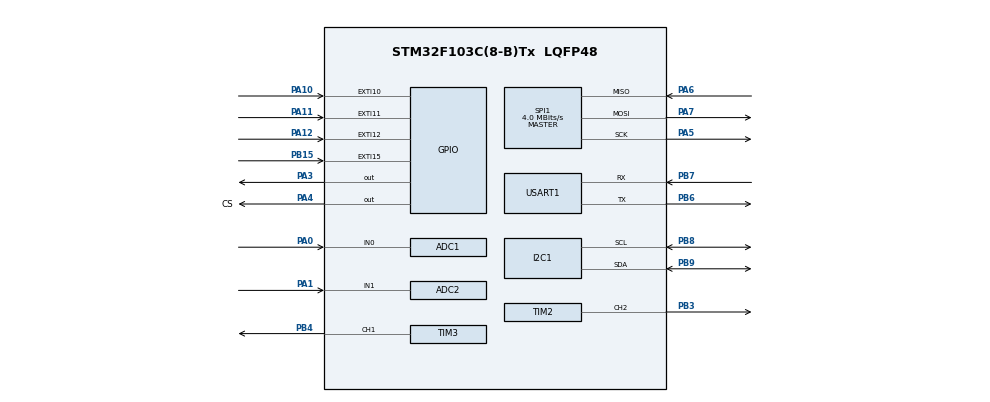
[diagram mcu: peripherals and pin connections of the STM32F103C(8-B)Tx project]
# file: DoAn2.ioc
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ADC1.Channel-0\#ChannelRegularConversion=ADC_CHANNEL_0
ADC1.NbrOfConversionFlag=1
ADC1.Rank-0\#ChannelRegularConversion=1
ADC1.SamplingTime-0\#ChannelRegularConversion=ADC_SAMPLETIME_1CYCLE_5
ADC1.master=1
ADC2.Channel-0\#ChannelRegularConversion=ADC_CHANNEL_1
ADC2.NbrOfConversionFlag=1
ADC2.Rank-0\#ChannelRegularConversion=1
ADC2.SamplingTime-0\#ChannelRegularConversion=ADC_SAMPLETIME_1CYCLE_5
Mcu.Family=STM32F1
Mcu.Name=STM32F103C(8-B)Tx
Mcu.Package=LQFP48
NVIC.PriorityGroup=NVIC_PRIORITYGROUP_4
PA0-WKUP.Signal=ADCx_IN0
PA1.Signal=ADCx_IN1
PA10.Signal=GPXTI10
PA11.Signal=GPXTI11
PA12.Signal=GPXTI12
PA13.Mode=Serial_Wire
PA13.Signal=SYS_JTMS-SWDIO
PA14.Mode=Serial_Wire
PA14.Signal=SYS_JTCK-SWCLK
PA3.Signal=GPIO_Output
PA4.GPIO_Label=CS
PA4.Signal=GPIO_Output
PA5.Mode=Full_Duplex_Master
PA5.Signal=SPI1_SCK
PA6.Mode=Full_Duplex_Master
PA6.Signal=SPI1_MISO
PA7.Mode=Full_Duplex_Master
PA7.Signal=SPI1_MOSI
PB15.Signal=GPXTI15
PB3.Signal=S_TIM2_CH2
PB4.Signal=S_TIM3_CH1
PB6.Mode=Asynchronous
PB6.Signal=USART1_TX
PB7.Mode=Asynchronous
PB7.Signal=USART1_RX
PB8.Mode=I2C
PB8.Signal=I2C1_SCL
PB9.Mode=I2C
PB9.Signal=I2C1_SDA
PD0-OSC_IN.Mode=HSE-External-Oscillator
PD0-OSC_IN.Signal=RCC_OSC_IN
PD1-OSC_OUT.Mode=HSE-External-Oscillator
PD1-OSC_OUT.Signal=RCC_OSC_OUT
ProjectManager.HeapSize=0x200
ProjectManager.StackSize=0x400
ProjectManager.TargetToolchain=MDK-ARM V5.32
RCC.APB1Freq_Value=8000000
RCC.APB2Freq_Value=8000000
SH.ADCx_IN0.0=ADC1_IN0,IN0
SH.ADCx_IN1.0=ADC2_IN1,IN1
SH.S_TIM2_CH2.0=TIM2_CH2,PWM Generation2 CH2
SH.S_TIM3_CH1.0=TIM3_CH1,PWM Generation1 CH1
SPI1.CalculateBaudRate=4.0 MBits/s
SPI1.Direction=SPI_DIRECTION_2LINES
SPI1.Mode=SPI_MODE_MASTER
SPI1.VirtualType=VM_MASTER
TIM2.AutoReloadPreload=TIM_AUTORELOAD_PRELOAD_ENABLE
TIM2.Channel-PWM\ Generation2\ CH2=TIM_CHANNEL_2
TIM2.Period=99
TIM2.Prescaler=8000
TIM3.Channel-PWM\ Generation1\ CH1=TIM_CHANNEL_1
USART1.VirtualMode=VM_ASYNC
board=custom

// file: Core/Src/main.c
/* USER CODE BEGIN Header */
/**
  ******************************************************************************
  * @file           : main.c
  * @brief          : Main program body
  ******************************************************************************
  * @attention
  *
  * Copyright (c) 2024 STMicroelectronics.
  * All rights reserved.
  *
  * This software is licensed under terms that can be found in the LICENSE file
  * in the root directory of this software component.
  * If no LICENSE file comes with this software, it is provided AS-IS.
  *
  ******************************************************************************
  */
/* USER CODE END Header */
#include "main.h"

ADC_HandleTypeDef hadc1;
ADC_HandleTypeDef hadc2;

I2C_HandleTypeDef hi2c1;

SPI_HandleTypeDef hspi1;

TIM_HandleTypeDef htim2;
TIM_HandleTypeDef htim3;

UART_HandleTypeDef huart1;

void SystemClock_Config(void);
static void MX_GPIO_Init(void);
static void MX_ADC1_Init(void);
static void MX_ADC2_Init(void);
static void MX_I2C1_Init(void);
static void MX_SPI1_Init(void);
static void MX_TIM2_Init(void);
static void MX_TIM3_Init(void);
static void MX_USART1_UART_Init(void);

int main(void)
{

  /* USER CODE BEGIN 1 */
	int Duty = 0;
  /* USER CODE END 1 */

  /* MCU Configuration--------------------------------------------------------*/

  /* Reset of all peripherals, Initializes the Flash interface and the Systick. */
  HAL_Init();

  /* Configure the system clock */
  SystemClock_Config();

  /* Initialize all configured peripherals */
  MX_GPIO_Init();
  MX_ADC1_Init();
  MX_ADC2_Init();
  MX_I2C1_Init();
  MX_SPI1_Init();
  MX_TIM2_Init();
  MX_TIM3_Init();
  MX_USART1_UART_Init();
  /* USER CODE BEGIN 2 */
	HAL_TIM_PWM_Start(&htim2,TIM_CHANNEL_2);
  /* USER CODE END 2 */

  /* Infinite loop */
  /* USER CODE BEGIN WHILE */
  while (1)
  {
		Duty += 1;
		__HAL_TIM_SET_COMPARE(&htim2,TIM_CHANNEL_2,Duty);
		HAL_Delay(100);
		if(Duty == 100){
			Duty = 0;
		}
    /* USER CODE END WHILE */

  }
}

void SystemClock_Config(void)
{
  RCC_OscInitTypeDef RCC_OscInitStruct = {0};
  RCC_ClkInitTypeDef RCC_ClkInitStruct = {0};
  RCC_PeriphCLKInitTypeDef PeriphClkInit = {0};

  /** Initializes the RCC Oscillators according to the specified parameters
  * in the RCC_OscInitTypeDef structure.
  */
  RCC_OscInitStruct.OscillatorType = RCC_OSCILLATORTYPE_HSI;
  RCC_OscInitStruct.HSIState = RCC_HSI_ON;
  RCC_OscInitStruct.HSICalibrationValue = RCC_HSICALIBRATION_DEFAULT;
  RCC_OscInitStruct.PLL.PLLState = RCC_PLL_NONE;
  if (HAL_RCC_OscConfig(&RCC_OscInitStruct) != HAL_OK)
  {
    Error_Handler();
  }

  /** Initializes the CPU, AHB and APB buses clocks
  */
  RCC_ClkInitStruct.ClockType = RCC_CLOCKTYPE_HCLK|RCC_CLOCKTYPE_SYSCLK
                              |RCC_CLOCKTYPE_PCLK1|RCC_CLOCKTYPE_PCLK2;
  RCC_ClkInitStruct.SYSCLKSource = RCC_SYSCLKSOURCE_HSI;
  RCC_ClkInitStruct.AHBCLKDivider = RCC_SYSCLK_DIV1;
  RCC_ClkInitStruct.APB1CLKDivider = RCC_HCLK_DIV1;
  RCC_ClkInitStruct.APB2CLKDivider = RCC_HCLK_DIV1;

  if (HAL_RCC_ClockConfig(&RCC_ClkInitStruct, FLASH_LATENCY_0) != HAL_OK)
  {
    Error_Handler();
  }
  PeriphClkInit.PeriphClockSelection = RCC_PERIPHCLK_ADC;
  PeriphClkInit.AdcClockSelection = RCC_ADCPCLK2_DIV2;
  if (HAL_RCCEx_PeriphCLKConfig(&PeriphClkInit) != HAL_OK)
  {
    Error_Handler();
  }
}

static void MX_ADC1_Init(void)
{

  ADC_ChannelConfTypeDef sConfig = {0};

  /** Common config
  */
  hadc1.Instance = ADC1;
  hadc1.Init.ScanConvMode = ADC_SCAN_DISABLE;
  hadc1.Init.ContinuousConvMode = DISABLE;
  hadc1.Init.DiscontinuousConvMode = DISABLE;
  hadc1.Init.ExternalTrigConv = ADC_SOFTWARE_START;
  hadc1.Init.DataAlign = ADC_DATAALIGN_RIGHT;
  hadc1.Init.NbrOfConversion = 1;
  if (HAL_ADC_Init(&hadc1) != HAL_OK)
  {
    Error_Handler();
  }

  /** Configure Regular Channel
  */
  sConfig.Channel = ADC_CHANNEL_0;
  sConfig.Rank = ADC_REGULAR_RANK_1;
  sConfig.SamplingTime = ADC_SAMPLETIME_1CYCLE_5;
  if (HAL_ADC_ConfigChannel(&hadc1, &sConfig) != HAL_OK)
  {
    Error_Handler();
  }

}

static void MX_ADC2_Init(void)
{

  ADC_ChannelConfTypeDef sConfig = {0};

  /** Common config
  */
  hadc2.Instance = ADC2;
  hadc2.Init.ScanConvMode = ADC_SCAN_DISABLE;
  hadc2.Init.ContinuousConvMode = DISABLE;
  hadc2.Init.DiscontinuousConvMode = DISABLE;
  hadc2.Init.ExternalTrigConv = ADC_SOFTWARE_START;
  hadc2.Init.DataAlign = ADC_DATAALIGN_RIGHT;
  hadc2.Init.NbrOfConversion = 1;
  if (HAL_ADC_Init(&hadc2) != HAL_OK)
  {
    Error_Handler();
  }

  /** Configure Regular Channel
  */
  sConfig.Channel = ADC_CHANNEL_1;
  sConfig.Rank = ADC_REGULAR_RANK_1;
  sConfig.SamplingTime = ADC_SAMPLETIME_1CYCLE_5;
  if (HAL_ADC_ConfigChannel(&hadc2, &sConfig) != HAL_OK)
  {
    Error_Handler();
  }

}

static void MX_I2C1_Init(void)
{

  hi2c1.Instance = I2C1;
  hi2c1.Init.ClockSpeed = 100000;
  hi2c1.Init.DutyCycle = I2C_DUTYCYCLE_2;
  hi2c1.Init.OwnAddress1 = 0;
  hi2c1.Init.AddressingMode = I2C_ADDRESSINGMODE_7BIT;
  hi2c1.Init.DualAddressMode = I2C_DUALADDRESS_DISABLE;
  hi2c1.Init.OwnAddress2 = 0;
  hi2c1.Init.GeneralCallMode = I2C_GENERALCALL_DISABLE;
  hi2c1.Init.NoStretchMode = I2C_NOSTRETCH_DISABLE;
  if (HAL_I2C_Init(&hi2c1) != HAL_OK)
  {
    Error_Handler();
  }

}

static void MX_SPI1_Init(void)
{

  /* SPI1 parameter configuration*/
  hspi1.Instance = SPI1;
  hspi1.Init.Mode = SPI_MODE_MASTER;
  hspi1.Init.Direction = SPI_DIRECTION_2LINES;
  hspi1.Init.DataSize = SPI_DATASIZE_8BIT;
  hspi1.Init.CLKPolarity = SPI_POLARITY_LOW;
  hspi1.Init.CLKPhase = SPI_PHASE_1EDGE;
  hspi1.Init.NSS = SPI_NSS_SOFT;
  hspi1.Init.BaudRatePrescaler = SPI_BAUDRATEPRESCALER_2;
  hspi1.Init.FirstBit = SPI_FIRSTBIT_MSB;
  hspi1.Init.TIMode = SPI_TIMODE_DISABLE;
  hspi1.Init.CRCCalculation = SPI_CRCCALCULATION_DISABLE;
  hspi1.Init.CRCPolynomial = 10;
  if (HAL_SPI_Init(&hspi1) != HAL_OK)
  {
    Error_Handler();
  }

}

static void MX_TIM2_Init(void)
{

  TIM_MasterConfigTypeDef sMasterConfig = {0};
  TIM_OC_InitTypeDef sConfigOC = {0};

  htim2.Instance = TIM2;
  htim2.Init.Prescaler = 8000;
  htim2.Init.CounterMode = TIM_COUNTERMODE_UP;
  htim2.Init.Period = 99;
  htim2.Init.ClockDivision = TIM_CLOCKDIVISION_DIV1;
  htim2.Init.AutoReloadPreload = TIM_AUTORELOAD_PRELOAD_ENABLE;
  if (HAL_TIM_PWM_Init(&htim2) != HAL_OK)
  {
    Error_Handler();
  }
  sMasterConfig.MasterOutputTrigger = TIM_TRGO_RESET;
  sMasterConfig.MasterSlaveMode = TIM_MASTERSLAVEMODE_DISABLE;
  if (HAL_TIMEx_MasterConfigSynchronization(&htim2, &sMasterConfig) != HAL_OK)
  {
    Error_Handler();
  }
  sConfigOC.OCMode = TIM_OCMODE_PWM1;
  sConfigOC.Pulse = 0;
  sConfigOC.OCPolarity = TIM_OCPOLARITY_HIGH;
  sConfigOC.OCFastMode = TIM_OCFAST_DISABLE;
  if (HAL_TIM_PWM_ConfigChannel(&htim2, &sConfigOC, TIM_CHANNEL_2) != HAL_OK)
  {
    Error_Handler();
  }
  HAL_TIM_MspPostInit(&htim2);

}

static void MX_TIM3_Init(void)
{

  TIM_MasterConfigTypeDef sMasterConfig = {0};
  TIM_OC_InitTypeDef sConfigOC = {0};

  htim3.Instance = TIM3;
  htim3.Init.Prescaler = 0;
  htim3.Init.CounterMode = TIM_COUNTERMODE_UP;
  htim3.Init.Period = 65535;
  htim3.Init.ClockDivision = TIM_CLOCKDIVISION_DIV1;
  htim3.Init.AutoReloadPreload = TIM_AUTORELOAD_PRELOAD_DISABLE;
  if (HAL_TIM_PWM_Init(&htim3) != HAL_OK)
  {
    Error_Handler();
  }
  sMasterConfig.MasterOutputTrigger = TIM_TRGO_RESET;
  sMasterConfig.MasterSlaveMode = TIM_MASTERSLAVEMODE_DISABLE;
  if (HAL_TIMEx_MasterConfigSynchronization(&htim3, &sMasterConfig) != HAL_OK)
  {
    Error_Handler();
  }
  sConfigOC.OCMode = TIM_OCMODE_PWM1;
  sConfigOC.Pulse = 0;
  sConfigOC.OCPolarity = TIM_OCPOLARITY_HIGH;
  sConfigOC.OCFastMode = TIM_OCFAST_DISABLE;
  if (HAL_TIM_PWM_ConfigChannel(&htim3, &sConfigOC, TIM_CHANNEL_1) != HAL_OK)
  {
    Error_Handler();
  }
  HAL_TIM_MspPostInit(&htim3);

}

static void MX_USART1_UART_Init(void)
{

  huart1.Instance = USART1;
  huart1.Init.BaudRate = 115200;
  huart1.Init.WordLength = UART_WORDLENGTH_8B;
  huart1.Init.StopBits = UART_STOPBITS_1;
  huart1.Init.Parity = UART_PARITY_NONE;
  huart1.Init.Mode = UART_MODE_TX_RX;
  huart1.Init.HwFlowCtl = UART_HWCONTROL_NONE;
  huart1.Init.OverSampling = UART_OVERSAMPLING_16;
  if (HAL_UART_Init(&huart1) != HAL_OK)
  {
    Error_Handler();
  }

}

static void MX_GPIO_Init(void)
{
  GPIO_InitTypeDef GPIO_InitStruct = {0};

  /* GPIO Ports Clock Enable */
  __HAL_RCC_GPIOD_CLK_ENABLE();
  __HAL_RCC_GPIOA_CLK_ENABLE();
  __HAL_RCC_GPIOB_CLK_ENABLE();

  /*Configure GPIO pin Output Level */
  HAL_GPIO_WritePin(GPIOA, GPIO_PIN_3|CS_Pin, GPIO_PIN_RESET);

  /*Configure GPIO pins : PA3 CS_Pin */
  GPIO_InitStruct.Pin = GPIO_PIN_3|CS_Pin;
  GPIO_InitStruct.Mode = GPIO_MODE_OUTPUT_PP;
  GPIO_InitStruct.Pull = GPIO_NOPULL;
  GPIO_InitStruct.Speed = GPIO_SPEED_FREQ_LOW;
  HAL_GPIO_Init(GPIOA, &GPIO_InitStruct);

  /*Configure GPIO pin : PB15 */
  GPIO_InitStruct.Pin = GPIO_PIN_15;
  GPIO_InitStruct.Mode = GPIO_MODE_IT_RISING;
  GPIO_InitStruct.Pull = GPIO_NOPULL;
  HAL_GPIO_Init(GPIOB, &GPIO_InitStruct);

  /*Configure GPIO pins : PA10 PA11 PA12 */
  GPIO_InitStruct.Pin = GPIO_PIN_10|GPIO_PIN_11|GPIO_PIN_12;
  GPIO_InitStruct.Mode = GPIO_MODE_IT_RISING;
  GPIO_InitStruct.Pull = GPIO_NOPULL;
  HAL_GPIO_Init(GPIOA, &GPIO_InitStruct);

}

void Error_Handler(void)
{
  __disable_irq();
  while (1)
  {
  }
}
